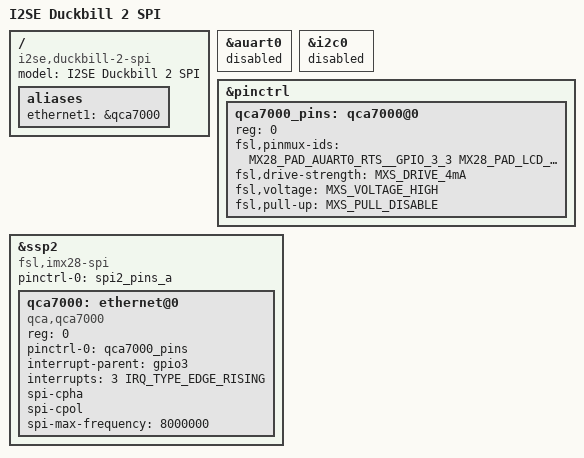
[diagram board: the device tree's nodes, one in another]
// SPDX-License-Identifier: GPL-2.0-or-later
/*
 * Copyright (C) 2015-2017 I2SE GmbH <info@i2se.com>
 * Copyright (C) 2016 Michael Heimpold <mhei@heimpold.de>
 */

/dts-v1/;
#include "imx28-duckbill-2.dts"

/ {
	model = "I2SE Duckbill 2 SPI";
	compatible = "i2se,duckbill-2-spi", "i2se,duckbill-2", "fsl,imx28";

	aliases {
		ethernet1 = &qca7000;
	};
};

&auart0 {
	status = "disabled";
};

&i2c0 {
	status = "disabled";
};

&pinctrl {
	qca7000_pins: qca7000@0 {
		reg = <0>;
		fsl,pinmux-ids = <
			MX28_PAD_AUART0_RTS__GPIO_3_3    /* Interrupt */
			MX28_PAD_LCD_D13__GPIO_1_13      /* QCA7K reset */
			MX28_PAD_LCD_D14__GPIO_1_14      /* GPIO 0 */
			MX28_PAD_LCD_D15__GPIO_1_15      /* GPIO 1 */
			MX28_PAD_LCD_D18__GPIO_1_18      /* GPIO 2 */
			MX28_PAD_LCD_D21__GPIO_1_21      /* GPIO 3 */
		>;
		fsl,drive-strength = <MXS_DRIVE_4mA>;
		fsl,voltage = <MXS_VOLTAGE_HIGH>;
		fsl,pull-up = <MXS_PULL_DISABLE>;
	};
};

&ssp2 {
	compatible = "fsl,imx28-spi";
	pinctrl-names = "default";
	pinctrl-0 = <&spi2_pins_a>;
	/delete-property/ bus-width;
	/delete-property/ vmmc-supply;
	status = "okay";

	qca7000: ethernet@0 {
		reg = <0>;
		compatible = "qca,qca7000";
		pinctrl-names = "default";
		pinctrl-0 = <&qca7000_pins>;
		interrupt-parent = <&gpio3>;
		interrupts = <3 IRQ_TYPE_EDGE_RISING>;
		spi-cpha;
		spi-cpol;
		spi-max-frequency = <8000000>;
	};
};
